AUTOSAR XML (schema 00047)
package /ASW_DEM
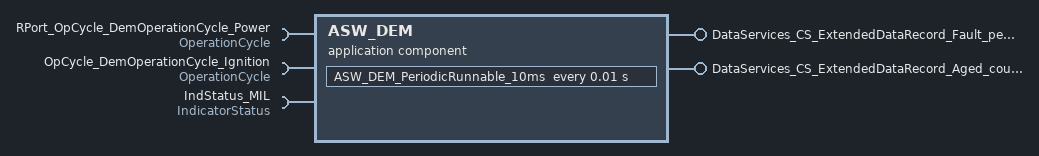
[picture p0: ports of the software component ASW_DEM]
  application sw component type ASW_DEM
    require port RPort_OpCycle_DemOperationCycle_Power: required-interface=OperationCycle
    provide port DataServices_CS_ExtendedDataRecord_Fault_pending_counter: provided-interface=DataServices_CS_ExtendedDataRecord_Fault_pending_counter
    provide port DataServices_CS_ExtendedDataRecord_Aged_counter: provided-interface=DataServices_CS_ExtendedDataRecord_Aged_counter
    require port OpCycle_DemOperationCycle_Ignition: required-interface=OperationCycle
    require port IndStatus_MIL: required-interface=IndicatorStatus
    behavior IB_Dem_SWC
      timing event TimingEvent_Dem_SWC: start-on-event=ASW_DEM_PeriodicRunnable_10ms, period=0.01
      operation invoked event OperationInvokedEvent_2: start-on-event=ASW_DEM_DataServices_CS_ExtendedDataRecord_Fault_pending_counter, operation=DataServices_CS_ExtendedDataRecord_Fault_pending_counter.ReadData
      operation invoked event OperationInvokedEvent_3: start-on-event=ASW_DEM_DataServices_CS_ExtendedDataRecord_Aged_counter, operation=DataServices_CS_ExtendedDataRecord_Aged_counter.ReadData
      4 x runnable:
        ASW_DEM_PeriodicRunnable_10ms: symbol=ASW_DEM_PeriodicRunnable_10ms_func
          7 x sync call:
            SynchronousServerCallPoint_10: operation=RPort_OpCycle_DemOperationCycle_Power.SetOperationCycleState
            SynchronousServerCallPoint_11: operation=RPort_OpCycle_DemOperationCycle_Power.GetOperationCycleState
            SynchronousServerCallPoint_12: operation=RPort_OpCycle_DemOperationCycle_Power.GetCycleQualified
            SynchronousServerCallPoint_13: operation=RPort_OpCycle_DemOperationCycle_Power.SetCycleQualified
            SynchronousServerCallPoint_6: operation=OpCycle_DemOperationCycle_Ignition.SetOperationCycleState
            SynchronousServerCallPoint_7: operation=OpCycle_DemOperationCycle_Ignition.GetOperationCycleState
            SynchronousServerCallPoint_8: operation=IndStatus_MIL.GetIndicatorStatus
        ASW_DEM_DataServices_CS_ExtendedDataRecord_Fault_pending_counter: symbol=ASW_DEM_DataServices_CS_ExtendedDataRecord_Fault_pending_counter_ReadData_func
        ASW_DEM_DataServices_CS_ExtendedDataRecord_Aged_counter: symbol=ASW_DEM_DataServices_CS_ExtendedDataRecord_Aged_counter_ReadData_func
        ASW_DEM_CBStatusComp_DemComponent: symbol=ASW_DEM_CBStatusComp_DemComponent_func
